# MCXN947_cm33_core0 register map
Vendor: nxp.com; File version: 1.0
CPU: CM33 r2p0, little endian, MPU, FPU, VTOR, 3 interrupt priority bits
Registers are 32-bit, read-write, reset 0x0 unless marked. A register's access mark holds for its fields unless they carry their own. Offsets are from the block's base; [hi:lo] are bit positions; 'fields as' and 'values as' point back to an identical list.

## SCG0 — SCG
Base 0x40044000
0x00 VERID ro — Version ID Register
  [31:0] VERSION — SCG Version Number
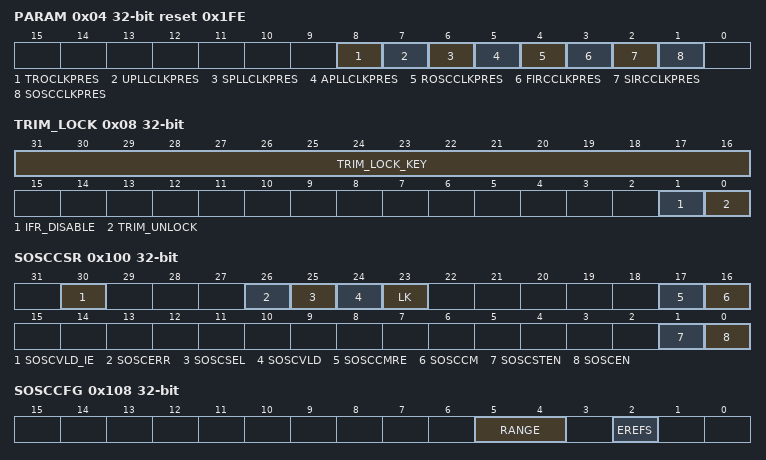
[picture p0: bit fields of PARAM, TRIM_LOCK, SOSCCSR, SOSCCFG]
0x04 PARAM ro reset 0x1FE — Parameter Register
  [8] TROCLKPRES — TRO Clock Present
    0=NOPRES (TRO clock source is not present); 1=PRES (TRO clock source is present)
  [7] UPLLCLKPRES — UPLL Clock Present
    0=NOPRES (UPLL clock source is not present); 1=PRES (UPLL clock source is present)
  [6] SPLLCLKPRES — SPLL Clock Present
    0=NOPRES (SPLL clock source is not present); 1=PRES (SPLL clock source is present)
  [5] APLLCLKPRES — APLL Clock Present
    0=NOPRES (APLL clock source is not present); 1=PRES (APLL clock source is present)
  [4] ROSCCLKPRES — ROSC Clock Present
    0=NOPRES (ROSC clock source is not present); 1=PRES (ROSC clock source is present)
  [3] FIRCCLKPRES — FIRC Clock Present
    0=NOPRES (FIRC clock source is not present); 1=PRES (FIRC clock source is present)
  [2] SIRCCLKPRES — SIRC Clock Present
    0=NOPRES (SIRC clock source is not present); 1=PRES (SIRC clock source is present)
  [1] SOSCCLKPRES — SOSC Clock Present
    0=NOPRES (SOSC clock source is not present); 1=PRES (SOSC clock source is present)
0x08 TRIM_LOCK
  [31:16] TRIM_LOCK_KEY
  [1] IFR_DISABLE
    0=ENABLED (IFR write access to SCG trim registers not disabled. The SCG Trim registers are reprogrammed with the IFR values after any system reset.); 1=DISABLED (IFR write access to SCG trim registers during system reset is blocked.)
  [0] TRIM_UNLOCK
    0=LOCKED (SCG Trim registers are locked and not writable.); 1=NOT_LOCKED (SCG Trim registers are unlocked and writable.)
0x10 CSR ro reset 0x3000000 — Clock Status Register
  [27:24] SCS — System Clock Source
    1=SOSC; 2=SIRC; 3=FIRC; 4=ROSC; 5=APLL; 6=SPLL; 7=UPLL; 8=TRO
0x14 RCCR reset 0x3000000 — Run Clock Control Register
  fields as CSR
0x100 SOSCCSR — SOSC Control Status Register
  [30] SOSCVLD_IE — SOSC Valid Interrupt Enable
    0=NOT_SOSC (SOSCVLD interrupt is not enabled); 1=SOSC (SOSCVLD interrupt is enabled)
  [26] SOSCERR write-1-clears — SOSC Clock Error
    0=DISABLED_OR_NO_ERROR (SOSC Clock Monitor is disabled or has not detected an error); 1=ENABLED_AND_ERROR (SOSC Clock Monitor is enabled and detected an error)
  [25] SOSCSEL ro — SOSC Selected
    0=NOT_SOSC (SOSC is not the system clock source); 1=SOSC (SOSC is the system clock source)
  [24] SOSCVLD ro — SOSC Valid
    0=DISABLED (SOSC is not enabled or clock is not valid); 1=ENABLED (SOSC is enabled and output clock is valid)
  [23] LK — Lock Register
    0=WRITE_ENABLED (This Control Status Register can be written); 1=WRITE_DISABLED (This Control Status Register cannot be written)
  [17] SOSCCMRE — SOSC Clock Monitor Reset Enable
    0=GENERATE_INTERRUPT (Clock monitor generates an interrupt when an error is detected); 1=GENERATE_RESET (Clock monitor generates a reset when an error is detected)
  [16] SOSCCM — SOSC Clock Monitor Enable
    0=DISABLED (SOSC Clock Monitor is disabled); 1=ENABLED (SOSC Clock Monitor is enabled)
  [1] SOSCSTEN — SOSC Stop Enable
    0=DISABLED (SOSC is disabled in Deep Sleep mode); 1=ENABLED (SOSC is enabled in Deep Sleep mode only if SOSCEN is set)
  [0] SOSCEN — SOSC Enable
    0=DISABLED (SOSC is disabled); 1=ENABLED (SOSC is enabled)
0x108 SOSCCFG — SOSC Configuration Register
  [5:4] RANGE — SOSC Range Select
    0=FREQ_16TO20MHZ (Frequency range select of 16-20 MHz.); 1=LOW_FREQ (Frequency range select of 20-30 MHz.); 2=MEDIUM_FREQ (Frequency range select of 30-50 MHz.); 3=HIGH_FREQ (Frequency range select of 50-66 MHz.)
  [2] EREFS — External Reference Select
    0=EXTERNAL (External reference clock selected. LDO can be disabled in this case.); 1=INTERNAL (Internal crystal oscillator of OSC selected.)
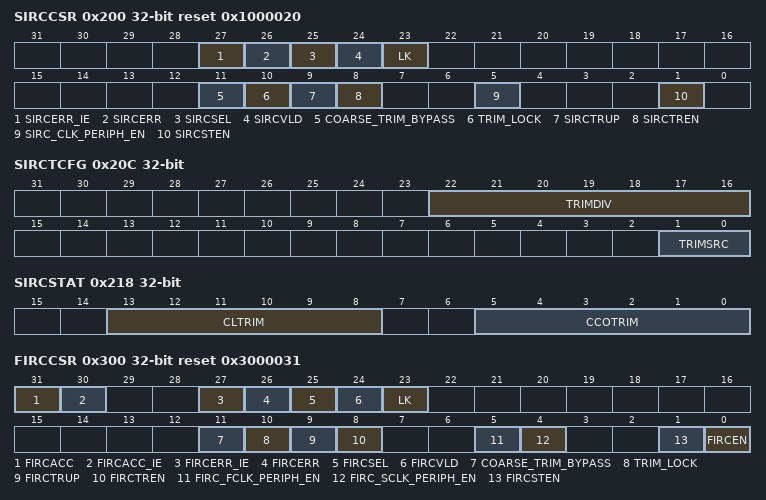
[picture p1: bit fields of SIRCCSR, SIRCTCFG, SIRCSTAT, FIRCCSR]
0x200 SIRCCSR reset 0x1000020 — SIRC Control Status Register
  [27] SIRCERR_IE — SIRC Clock Error Interrupt Enable
    0=ERROR_NOT_DETECTED (SIRCERR interrupt is not enabled); 1=ERROR_DETECTED (SIRCERR interrupt is enabled)
  [26] SIRCERR write-1-clears — SIRC Clock Error
    0=ERROR_NOT_DETECTED (Error not detected with the SIRC trimming); 1=ERROR_DETECTED (Error detected with the SIRC trimming)
  [25] SIRCSEL ro — SIRC Selected
    0=NOT_SIRC (SIRC is not the system clock source); 1=SIRC (SIRC is the system clock source)
  [24] SIRCVLD ro — SIRC Valid
    0=DISABLED_OR_NOT_VALID (SIRC is not enabled or clock is not valid); 1=ENABLED_AND_VALID (SIRC is enabled and output clock is valid)
  [23] LK — Lock Register
    0=WRITE_ENABLED (Control Status Register can be written); 1=WRITE_DISABLED (Control Status Register cannot be written)
  [11] COARSE_TRIM_BYPASS — Coarse Auto Trim Bypass
    0=NOT_BYPASSED (SIRC coarse auto-trim is not bypassed); 1=BYPASSED (SIRC coarse auto-trim is bypassed)
  [10] TRIM_LOCK ro — SIRC TRIM LOCK
    0=SIRC_NOT_LOCKED (SIRC auto trim not locked to target frequency range); 1=SIRC_LOCKED (SIRC auto trim locked to target frequency range)
  [9] SIRCTRUP — SIRC Trim Update
    0=DISABLED (Disables SIRC trimming updates); 1=ENABLED (Enables SIRC trimming updates)
  [8] SIRCTREN — SIRC 12 MHz Trim Enable (SIRCCFG[RANGE]=1)
    0=DISABLED (Disables trimming SIRC to an external clock source); 1=ENABLED (Enables trimming SIRC to an external clock source)
  [5] SIRC_CLK_PERIPH_EN — SIRC Clock to Peripherals Enable
    0=DISABLED (SIRC clock to peripherals is disabled); 1=ENABLED (SIRC clock to peripherals is enabled)
  [1] SIRCSTEN — SIRC Stop Enable
    0=DISABLED (SIRC is disabled in Deep Sleep mode); 1=ENABLED (SIRC is enabled in Deep Sleep mode)
0x20C SIRCTCFG — SIRC Trim Configuration Register
  [22:16] TRIMDIV — SIRC Trim Predivider
  [1:0] TRIMSRC — Trim Source
    2=SOSC; 3=ROSC (ROSC (32.768 kHz))
0x218 SIRCSTAT (reset mask 0xFFFFC0C0) — SIRC Auto-trimming Status Register
  [13:8] CLTRIM, [5:0] CCOTRIM
0x300 FIRCCSR reset 0x3000031 (reset mask 0x7FFFFFFF) — FIRC Control Status Register
  [31] FIRCACC ro — FIRC Frequency Accurate
    0=NOT_ENABLED_OR_NOT_VALID (FIRC is not enabled or clock is not accurate.); 1=ENABLED_AND_VALID (FIRC is enabled and output clock is accurate. The clock is accurate after 4096 clock cycles of 144 MHz (RANGE=1) or 1365 clock cycles of 48 MHz(RANGE=0) from the FIRC analog.)
  [30] FIRCACC_IE — FIRC Accurate Interrupt Enable
    0=FIRCACCNOT (FIRCACC interrupt is not enabled); 1=FIRCACCYES (FIRCACC interrupt is enabled)
  [27] FIRCERR_IE — FIRC Clock Error Interrupt Enable
    0=ERROR_NOT_DETECTED (FIRCERR interrupt is not enabled); 1=ERROR_DETECTED (FIRCERR interrupt is enabled)
  [26] FIRCERR write-1-clears — FIRC Clock Error
    0=ERROR_NOT_DETECTED (Error not detected with the FIRC trimming); 1=ERROR_DETECTED (Error detected with the FIRC trimming)
  [25] FIRCSEL ro — FIRC Selected
    0=NOT_FIRC (FIRC is not the system clock source); 1=FIRC (FIRC is the system clock source)
  [24] FIRCVLD ro — FIRC Valid status
    0=NOT_ENABLED_OR_NOT_VALID (FIRC is not enabled or clock is not valid.); 1=ENABLED_AND_VALID (FIRC is enabled and output clock is valid. The clock is valid after there is an output clock from the FIRC analog.)
  [23] LK — Lock Register
    values as SIRCCSR.LK
  [11] COARSE_TRIM_BYPASS — Coarse Auto Trim Bypass
    0=NOT_BYPASSED (FIRC coarse auto trim is not bypassed); 1=BYPASSED (FIRC coarse auto trim is bypassed)
  [10] TRIM_LOCK ro — FIRC TRIM LOCK
    0=FIRC_NOT_LOCKED (FIRC auto trim not locked to target frequency range); 1=FIRC_LOCKED (FIRC auto trim locked to target frequency range)
  [9] FIRCTRUP — FIRC Trim Update
    0=DISABLED (Disables FIRC trimming updates); 1=ENABLED (Enables FIRC trimming updates)
  [8] FIRCTREN — FIRC 144 MHz Trim Enable (FIRCCFG[RANGE]=1)
    0=DISABLED (Disables trimming FIRC to an external clock source); 1=ENABLED (Enables trimming FIRC to an external clock source)
  [5] FIRC_FCLK_PERIPH_EN — FIRC 144 MHz Clock to peripherals Enable
    0=DISABLED (FIRC 144 MHz to peripherals is disabled); 1=ENABLED (FIRC 144 MHz to peripherals is enabled)
  [4] FIRC_SCLK_PERIPH_EN — FIRC 48 MHz Clock to peripherals Enable
    0=DISABLED (FIRC 48 MHz to peripherals is disabled); 1=ENABLED (FIRC 48 MHz to peripherals is enabled)
  [1] FIRCSTEN — FIRC Stop Enable
    0=DISABLED_IN_STOP_MODES (FIRC is disabled in Deep Sleep mode); 1=ENABLED_IN_STOP_MODES (FIRC is enabled in Deep Sleep mode)
  [0] FIRCEN — FIRC Enable
    0=DISABLED (FIRC is disabled); 1=ENABLED (FIRC is enabled)
0x308 FIRCCFG — FIRC Configuration Register
  [0] RANGE — Frequency Range
    0=FIRC_48MHZ (48 MHz FIRC clock selected); 1=FIRC_144MHZ (144 MHz FIRC clock selected)
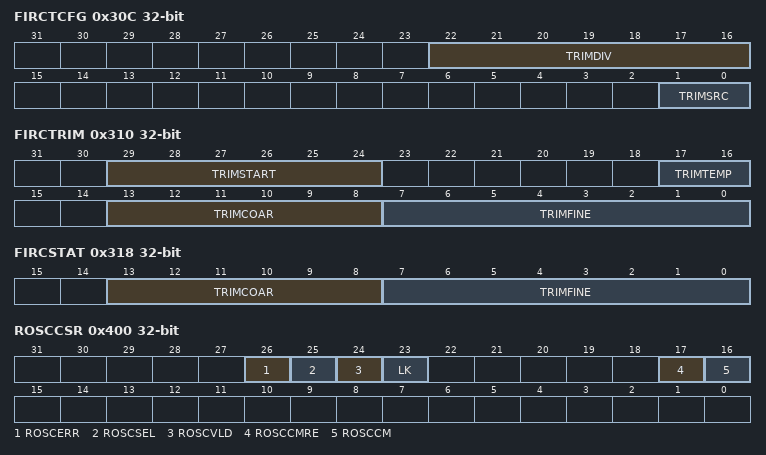
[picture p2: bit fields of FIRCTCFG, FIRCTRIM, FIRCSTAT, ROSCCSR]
0x30C FIRCTCFG — FIRC Trim Configuration Register
  [22:16] TRIMDIV — FIRC Trim Predivider
  [1:0] TRIMSRC — Trim Source
    0=USB0 (USB0 Start of Frame (1 kHz). This option does not use TRIMDIV); 2=SOSC; 3=ROSC
0x310 FIRCTRIM (reset mask 0xC0FCC000)
  [29:24] TRIMSTART
  [17:16] TRIMTEMP — Trim Temperature
  [13:8] TRIMCOAR — Trim Coarse
  [7:0] TRIMFINE
0x318 FIRCSTAT (reset mask 0xFFFFC000) — FIRC Auto-trimming Status Register
  [13:8] TRIMCOAR — Trim Coarse
  [7:0] TRIMFINE
0x400 ROSCCSR — ROSC Control Status Register
  [26] ROSCERR write-1-clears — ROSC Clock Error
    0=DISABLED_OR_NO_ERROR (ROSC Clock Monitor is disabled or has not detected an error); 1=ENABLED_AND_ERROR (ROSC Clock Monitor is enabled and detected an RTC loss of clock error)
  [25] ROSCSEL ro — ROSC Selected
    0=NOT_ROSC (ROSC is not the system clock source); 1=ROSC (ROSC is the system clock source)
  [24] ROSCVLD ro — ROSC Valid
    0=DISABLED_OR_NOT_VALID (ROSC is not enabled or clock is not valid); 1=ENABLED_AND_VALID (ROSC is enabled and output clock is valid)
  [23] LK — Lock Register
    values as SIRCCSR.LK
  [17] ROSCCMRE — ROSC Clock Monitor Reset Enable
    values as SOSCCSR.SOSCCMRE
  [16] ROSCCM — ROSC Clock Monitor
    0=DISABLED (ROSC clock monitor is disabled); 1=ENABLED (ROSC clock monitor is enabled)
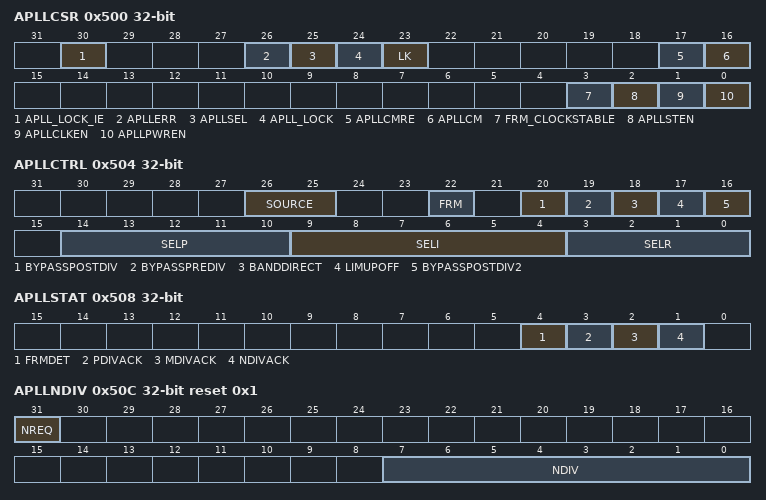
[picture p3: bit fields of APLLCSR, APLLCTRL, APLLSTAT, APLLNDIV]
0x500 APLLCSR — APLL Control Status Register
  [30] APLL_LOCK_IE — APLL LOCK Interrupt Enable
    0=NOT_APLL (APLL_LOCK interrupt is not enabled); 1=APLL (APLL_LOCK interrupt is enabled)
  [26] APLLERR write-1-clears — APLL Clock Error
    0=DISABLED_OR_NO_ERROR (APLL Clock Monitor is disabled or has not detected an error); 1=ENABLED_AND_ERROR (APLL Clock Monitor is enabled and detected an error)
  [25] APLLSEL ro — APLL Selected
    0=NOT_APLL (APLL is not the system clock source); 1=APLL (APLL is the system clock source)
  [24] APLL_LOCK ro
    0=DISABLED_OR_NOT_VALID (APLL is not powered on or not locked); 1=ENABLED_AND_VALID (APLL is locked)
  [23] LK — Lock Register
    values as SIRCCSR.LK
  [17] APLLCMRE — APLL Clock Monitor Reset Enable
    values as SOSCCSR.SOSCCMRE
  [16] APLLCM — APLL Clock Monitor
    0=DISABLED (APLL Clock Monitor is disabled); 1=ENABLED (APLL Clock Monitor is enabled)
  [3] FRM_CLOCKSTABLE — Free running mode clock stable
    0=DISABLED (Free running mode clockstable is disabled); 1=ENABLED (Free running mode clockstable is enabled)
  [2] APLLSTEN — APLL Stop Enable
    0=DISABLED_IN_STOP (APLL is disabled in Deep Sleep mode); 1=ENABLED_IN_STOP (APLL is enabled in Deep Sleep mode)
  [1] APLLCLKEN — APLL Clock Enable
    0=DISABLED (APLL clock is disabled); 1=ENABLED (APLL clock is enabled)
  [0] APLLPWREN — APLL Power Enable
    0=DISABLED (APLL clock is powered off); 1=ENABLED (APLL clock is powered on)
0x504 APLLCTRL — APLL Control Register
  [26:25] SOURCE — Clock Source
    0=SOSC; 1=FIRC (FIRC 48 MHz clock. FIRC_SCLK_PERIPH_EN must be set to use FIRC 48 MHz clock.); 2=ROSC; 3=RSVD (No clock)
  [22] FRM — Free Running Mode Enable
    0=DISABLED (Free running mode disabled); 1=ENABLED (Free running mode enabled)
  [20] BYPASSPOSTDIV — Bypass of the postdivider
    0=DISABLED (Use the postdivider.); 1=ENABLED (Bypass of the postdivider)
  [19] BYPASSPREDIV — Bypass of the predivider
    0=DISABLED (Use the predivider.); 1=ENABLED (Bypass of the predivider.)
  [18] BANDDIRECT — Control of the bandwidth of the PLL.
    0=DISABLED (The bandwidth is changed synchronously with the feedback-divider); 1=ENABLED (Modifies the bandwidth of the PLL directly)
  [17] LIMUPOFF — Up Limiter
    0=DISABLED (Application set to non-Spectrum and Fractional applications.); 1=ENABLED (Application set to Spectrum and Fractional applications.)
  [16] BYPASSPOSTDIV2 — Bypass of Divide-by-2 Divider
    0=NOT_BYPASSED (Use the divide-by-2 divider in the postdivider); 1=BYPASSED (Bypass of the divide-by-2 divider in the postdivider)
  [14:10] SELP — Bandwidth select P (proportional) value.
  [9:4] SELI — Bandwidth select I (integration) value.
  [3:0] SELR — Bandwidth select R (resistor) value.
0x508 APLLSTAT ro — APLL Status Register
  [4] FRMDET — Free running detector (active high)
    0=DISABLED (Free running is not detected); 1=ENABLED (Free running is detected)
  [3] PDIVACK — Postdivider(P) ratio change acknowledge.
    0=DISABLED (The postdivider (P) ratio change is not accepted by the analog PLL); 1=ENABLED (The postdivider (P) ratio change is accepted by the analog PLL)
  [2] MDIVACK — Feedback(M) divider ratio change acknowledge.
    0=DISABLED (The feedback (M) ratio change is not accepted by the analog PLL); 1=ENABLED (The feedback (M) ratio change is accepted by the analog PLL)
  [1] NDIVACK — Predivider(N) ratio change acknowledge.
    0=DISABLED (The predivider (N) ratio change is not accepted by the analog PLL); 1=ENABLED (The predivider (N) ratio change is accepted by the analog PLL)
0x50C APLLNDIV reset 0x1 — APLL N Divider Register
  [31] NREQ — Predivider ratio change request.
    0=DISABLED (Predivider ratio change is not requested); 1=ENABLED (Predivider ratio change is requested)
  [7:0] NDIV — Predivider divider ratio (N-divider).
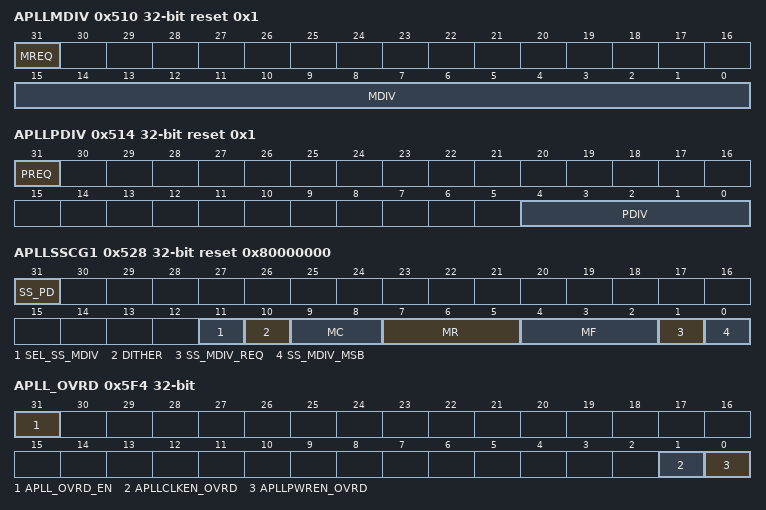
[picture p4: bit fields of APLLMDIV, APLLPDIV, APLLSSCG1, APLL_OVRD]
0x510 APLLMDIV reset 0x1 — APLL M Divider Register
  [31] MREQ — Feedback ratio change request.
    0=DISABLED (Feedback ratio change is not requested); 1=ENABLED (Feedback ratio change is requested)
  [15:0] MDIV — Feedback divider divider ratio (M-divider).
0x514 APLLPDIV reset 0x1 — APLL P Divider Register
  [31] PREQ — Postdivider ratio change request
    0=DISABLED (Postdivider ratio change is not requested); 1=ENABLED (Postdivider ratio change is requested)
  [4:0] PDIV — Postdivider divider ratio (P-divider)
0x518 APLLLOCK_CNFG reset 0x4F4C — APLL LOCK Configuration Register
  [16:0] LOCK_TIME — Configures the number of reference clocks to count before APLL is considered locked.
0x520 APLLSSCGSTAT ro — APLL SSCG Status Register
  [0] SS_MDIV_ACK — SS_MDIV change acknowledge
    0=DISABLED (The SS_MDIV, MF, MR, and MC ratio change is not accepted by the analog PLL); 1=ENABLED (The SS_MDIV, MF, MR, and MC ratio change is accepted by the analog PLL)
0x524 APLLSSCG0 — APLL Spread Spectrum Control 0 Register
  [31:0] SS_MDIV_LSB — SS_MDIV
0x528 APLLSSCG1 reset 0x80000000 — APLL Spread Spectrum Control 1 Register
  [31] SS_PD — SSCG Power Down
    0=DISABLED (SSCG is powered on); 1=ENABLED (SSCG is powered off)
  [11] SEL_SS_MDIV — SS_MDIV select.
    0=DISABLED (Feedback divider ratio is MDIV[15:0]); 1=ENABLED (Feedback divider ratio is SS_MDIV[32:0])
  [10] DITHER — Dither Enable
    0=DISABLED (Dither is not enabled); 1=ENABLED (Dither is enabled)
  [9:8] MC — Modulation Waveform Control
    0=NO_COMP (MC[1:0] no compensation); 3=MAX_COMP (MC[1:0] maximum compensation)
  [7:5] MR — Modulation Depth Control
  [4:2] MF — Modulation Frequency Control
  [1] SS_MDIV_REQ — SS_MDIV[32:0] change request.
    0=DISABLED (SS_MDIV change is not requested); 1=ENABLED (SS_MDIV change is requested)
  [0] SS_MDIV_MSB — SS_MDIV[32]
0x5F4 APLL_OVRD — APLL Override Register
  [31] APLL_OVRD_EN — APLL Override Enable
    0=DISABLED (APLL override is disabled); 1=ENABLED (APLL override is enabled)
  [1] APLLCLKEN_OVRD — APLL Clock Enable Override if APLL_OVRD_EN=1
    values as APLLCSR.APLLCLKEN
  [0] APLLPWREN_OVRD — APLL Power Enable Override if APLL_OVRD_EN=1
    values as APLLCSR.APLLPWREN
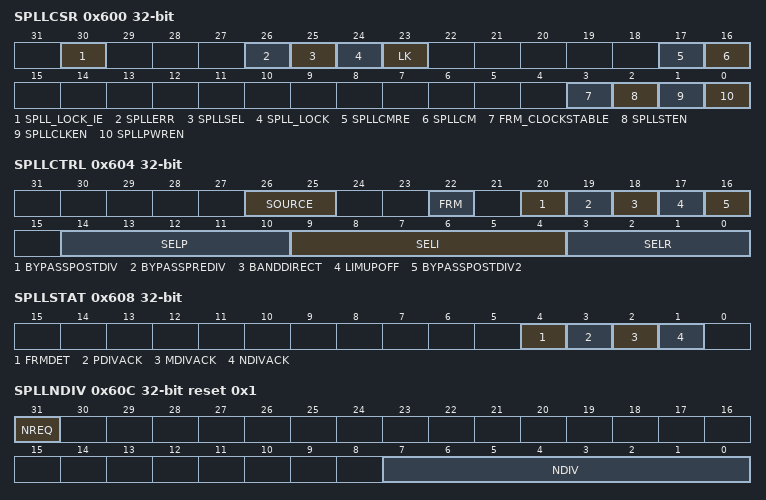
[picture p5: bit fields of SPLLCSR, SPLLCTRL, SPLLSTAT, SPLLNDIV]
0x600 SPLLCSR — SPLL Control Status Register
  [30] SPLL_LOCK_IE — SPLL LOCK Interrupt Enable
    0=NOT_SPLL (SPLL_LOCK interrupt is not enabled); 1=SPLL (SPLL_LOCK interrupt is enabled)
  [26] SPLLERR write-1-clears — SPLL Clock Error
    0=DISABLED_OR_NO_ERROR (SPLL Clock Monitor is disabled or has not detected an error); 1=ENABLED_AND_ERROR (SPLL Clock Monitor is enabled and detected an error)
  [25] SPLLSEL ro — SPLL Selected
    0=NOT_SPLL (SPLL is not the system clock source); 1=SPLL (SPLL is the system clock source)
  [24] SPLL_LOCK ro
    0=DISABLED_OR_NOT_VALID (SPLL is not powered on or not locked); 1=ENABLED_AND_VALID (SPLL is locked)
  [23] LK — Lock Register
    values as SIRCCSR.LK
  [17] SPLLCMRE — SPLL Clock Monitor Reset Enable
    values as SOSCCSR.SOSCCMRE
  [16] SPLLCM — SPLL Clock Monitor
    0=DISABLED (SPLL Clock Monitor is disabled); 1=ENABLED (SPLL Clock Monitor is enabled)
  [3] FRM_CLOCKSTABLE — Free running mode clock stable
    values as APLLCSR.FRM_CLOCKSTABLE
  [2] SPLLSTEN — SPLL Stop Enable
    0=DISABLED_IN_STOP (SPLL is disabled in Deep Sleep mode); 1=ENABLED_IN_STOP (SPLL is enabled in Deep Sleep mode)
  [1] SPLLCLKEN — SPLL Clock Enable
    0=DISABLED (SPLL clock is disabled); 1=ENABLED (SPLL clock is enabled)
  [0] SPLLPWREN — SPLL Power Enable
    0=DISABLED (SPLL clock is powered off); 1=ENABLED (SPLL clock is powered on)
0x604 SPLLCTRL — SPLL Control Register
  [26:25] SOURCE — Clock Source
    values as APLLCTRL.SOURCE
  [22] FRM — Free Running Mode Enable
    values as APLLCTRL.FRM
  [20] BYPASSPOSTDIV — Bypass of the postdivider.
    0=DISABLED (Use the postdivider); 1=ENABLED (Bypass of the postdivider)
  [19] BYPASSPREDIV — Bypass of the predivider.
    0=DISABLED (Use the predivider); 1=ENABLED (Bypass of the predivider)
  [18] BANDDIRECT — Control of the bandwidth of the PLL.
    values as APLLCTRL.BANDDIRECT
  [17] LIMUPOFF — Up Limiter.
    values as APLLCTRL.LIMUPOFF
  [16] BYPASSPOSTDIV2 — Bypass of Divide-by-2 Divider
    0=NOT_BYPASSED (Use the divide-by-2 divider in the postdivider.); 1=BYPASSED (Bypass of the divide-by-2 divider in the postdivider)
  [14:10] SELP — Bandwidth select P (proportional) value.
  [9:4] SELI — Bandwidth select I (integration) value.
  [3:0] SELR — Bandwidth select R (resistor) value.
0x608 SPLLSTAT ro — SPLL Status Register
  [4] FRMDET — Free running detector (active high)
    values as APLLSTAT.FRMDET
  [3] PDIVACK — Postdivider (P) ratio change acknowledge
    values as APLLSTAT.PDIVACK
  [2] MDIVACK — Feedback (M) divider ratio change acknowledge
    0=DISABLED (The feedback (M) ratio change is not accepted by the analog PLL.); 1=ENABLED (The feedback (M) ratio change is accepted by the analog PLL.)
  [1] NDIVACK — Predivider (N) ratio change acknowledge
    0=DISABLED (The predivider (N) ratio change is not accepted by the analog PLL.); 1=ENABLED (The predivider (N) ratio change is accepted by the analog PLL.)
0x60C SPLLNDIV reset 0x1 — SPLL N Divider Register
  fields as APLLNDIV
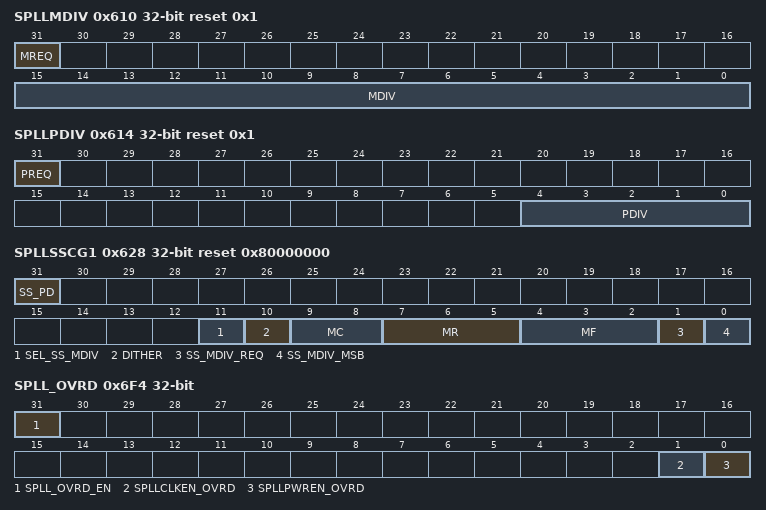
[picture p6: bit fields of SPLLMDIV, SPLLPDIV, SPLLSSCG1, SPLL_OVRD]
0x610 SPLLMDIV reset 0x1 — SPLL M Divider Register
  fields as APLLMDIV
0x614 SPLLPDIV reset 0x1 — SPLL P Divider Register
  fields as APLLPDIV
0x618 SPLLLOCK_CNFG reset 0x4F4C — SPLL LOCK Configuration Register
  [16:0] LOCK_TIME — Configures the number of reference clocks to count before SPLL is considered locked.
0x620 SPLLSSCGSTAT ro — SPLL SSCG Status Register
  fields as APLLSSCGSTAT
0x624 SPLLSSCG0 — SPLL Spread Spectrum Control 0 Register
  [31:0] SS_MDIV_LSB — SS_MDIV[31:0]
0x628 SPLLSSCG1 reset 0x80000000 — SPLL Spread Spectrum Control 1 Register
  fields as APLLSSCG1
0x6F4 SPLL_OVRD — SPLL Override Register
  [31] SPLL_OVRD_EN — SPLL Override Enable
    0=DISABLED (SPLL override is disabled); 1=ENABLED (SPLL override is enabled)
  [1] SPLLCLKEN_OVRD — SPLL Clock Enable Override if SPLL_OVRD_EN=1
    values as SPLLCSR.SPLLCLKEN
  [0] SPLLPWREN_OVRD — SPLL Power Enable Override if SPLL_OVRD_EN=1
    values as SPLLCSR.SPLLPWREN
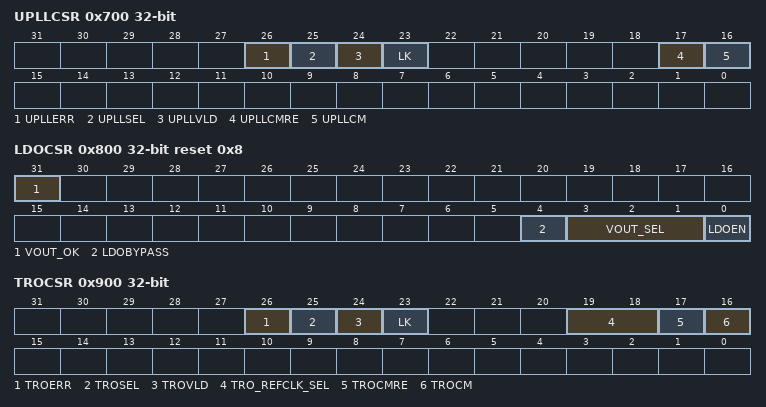
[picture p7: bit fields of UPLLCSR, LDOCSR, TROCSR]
0x700 UPLLCSR — UPLL Control Status Register
  [26] UPLLERR write-1-clears — UPLL Clock Error
    0=DISABLED_OR_NO_ERROR (UPLL Clock Monitor is disabled or has not detected an error); 1=ENABLED_AND_ERROR (UPLL Clock Monitor is enabled and detected an error)
  [25] UPLLSEL ro — UPLL Selected
    0=NOT_USB_PLL (UPLL is not the system clock source); 1=USB_PLL (UPLL is the system clock source)
  [24] UPLLVLD ro — UPLL Valid
    0=DISABLED_OR_NOT_VALID (UPLL is not enabled or clock is not valid); 1=ENABLED_AND_VALID (UPLL is enabled and output clock is valid)
  [23] LK — Lock Register
    values as SIRCCSR.LK
  [17] UPLLCMRE — UPLL Clock Monitor Reset Enable
    values as SOSCCSR.SOSCCMRE
  [16] UPLLCM — UPLL Clock Monitor
    0=DISABLED (UPLL Clock Monitor is disabled); 1=ENABLED (UPLL Clock Monitor is enabled)
0x800 LDOCSR reset 0x8 — LDO Control and Status Register
  [31] VOUT_OK ro — LDO VOUT OK Inform.
    0=DISABLED (LDO output VOUT is not OK); 1=ENABLED (LDO output VOUT is OK)
  [4] LDOBYPASS
    0=DISABLED (LDO is not bypassed); 1=ENABLED (LDO is bypassed)
  [3:1] VOUT_SEL — LDO output voltage select
    0=VOUT_1V_1; 1=VOUT_1V_2; 2=VOUT_1V_3; 3=VOUT_105V; 4=VOUT_11V; 5=VOUT_115V; 6=VOUT_12V; 7=VOUT_125V
  [0] LDOEN — LDO Enable
    0=DISABLED (LDO is disabled); 1=ENABLED (LDO is enabled)
0x900 TROCSR — TRO Control Status Register
  [26] TROERR write-1-clears — TRO Clock Error
    0=DISABLED_OR_NO_ERROR (TRO clock monitor is disabled or has not detected an error); 1=ENABLED_AND_ERROR (TRO clock monitor is enabled and detected an error)
  [25] TROSEL ro — TRO Selected
    0=NOT_USB_PLL (TRO is not the system clock source); 1=USB_PLL (TRO is the system clock source)
  [24] TROVLD ro — TRO Valid
    0=DISABLED_OR_NOT_VALID (TRO is not enabled or clock is not valid); 1=ENABLED_AND_VALID (TRO is enabled and output clock is valid)
  [23] LK — Lock Register
    values as SIRCCSR.LK
  [19:18] TRO_REFCLK_SEL — TRO reference clock selection
    0=V00 (SOSC); 1=V01 (SIRC); 2=V10 (FIRC (144 MHz or 48 MHz, based on RANGE selection))
  [17] TROCMRE — TRO Clock Monitor Reset Enable
    values as SOSCCSR.SOSCCMRE
  [16] TROCM — TRO Clock Monitor
    0=DISABLED (TRO Clock Monitor is disabled); 1=ENABLED (TRO Clock Monitor is enabled)
